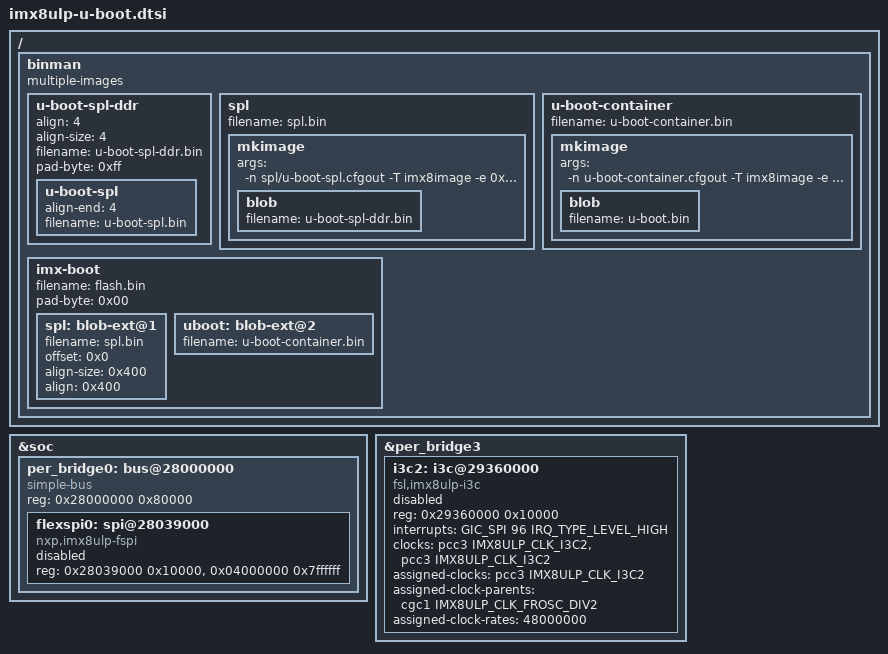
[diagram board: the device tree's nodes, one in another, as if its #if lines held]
// SPDX-License-Identifier: GPL-2.0+

#include <dt-bindings/reset/imx8ulp-pcc-reset.h>
#include <dt-bindings/reset/imx8ulp-sim-reset.h>

#ifdef CONFIG_BINMAN
/ {
	binman: binman {
		multiple-images;
	};
};

&binman {
	u-boot-spl-ddr {
		align = <4>;
		align-size = <4>;
		filename = "u-boot-spl-ddr.bin";
		pad-byte = <0xff>;

		u-boot-spl {
			align-end = <4>;
			filename = "u-boot-spl.bin";
		};
	};

	spl {
		filename = "spl.bin";

		mkimage {
			args = "-n spl/u-boot-spl.cfgout -T imx8image -e 0x22020000";

			blob {
				filename = "u-boot-spl-ddr.bin";
			};
		};
	};

	u-boot-container {
		filename = "u-boot-container.bin";

		mkimage {
			args = "-n u-boot-container.cfgout -T imx8image -e 0x0";

			blob {
				filename = "u-boot.bin";
			};
		};
	};

	imx-boot {
		filename = "flash.bin";
		pad-byte = <0x00>;

		spl: blob-ext@1 {
			filename = "spl.bin";
			offset = <0x0>;
			align-size = <0x400>;
			align = <0x400>;
		};

		uboot: blob-ext@2 {
			filename = "u-boot-container.bin";
		};
	};
};
#endif

&soc {
	per_bridge0: bus@28000000 {
		compatible = "simple-bus";
		reg = <0x28000000 0x80000>;
		#address-cells = <1>;
		#size-cells = <1>;
		ranges;

		flexspi0: spi@28039000 {
			#address-cells = <1>;
			#size-cells = <0>;
			compatible = "nxp,imx8ulp-fspi";
			reg = <0x28039000 0x10000>,
				<0x04000000 0x7ffffff>;
			reg-names = "fspi_base", "fspi_mmap";
			status = "disabled";
		};
	};
};

&per_bridge3 {
	i3c2: i3c@29360000 {
		compatible = "fsl,imx8ulp-i3c";
		reg = <0x29360000 0x10000>;
		#address-cells = <1>;
		#size-cells = <0>;
		interrupts = <GIC_SPI 96 IRQ_TYPE_LEVEL_HIGH>;
		clocks = <&pcc3 IMX8ULP_CLK_I3C2>,
			 <&pcc3 IMX8ULP_CLK_I3C2>;
		clock-names = "per", "ipg";
		assigned-clocks = <&pcc3 IMX8ULP_CLK_I3C2>;
		assigned-clock-parents = <&cgc1 IMX8ULP_CLK_FROSC_DIV2>;
		assigned-clock-rates = <48000000>;
		status = "disabled";
	};
};
